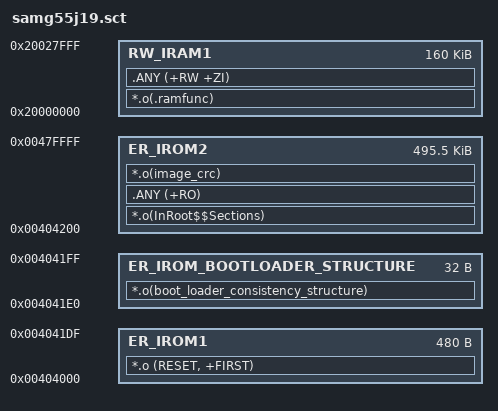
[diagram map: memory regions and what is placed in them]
; *************************************************************
; *** Scatter-Loading Description File generated by uVision ***
; *************************************************************

LR_IROM1 0x00404000 0x0007C000  {    ; load region size_region
  ER_IROM1 0x00404000 0x000001E0  {  ; load address = execution address
   *.o (RESET, +FIRST)
  }
  ER_IROM_BOOTLOADER_STRUCTURE 0x004041E0 0x00000020  {  ; load address = execution address
   *.o(boot_loader_consistency_structure)
  } 
  ER_IROM2 0x00404200 0x0007BE00  {  ; load address = execution address
  *.o(InRoot$$Sections)
   .ANY (+RO)
   *.o(image_crc)
  }
  RW_IRAM1 0x20000000 0x00028000  {  ; RW data
   *.o(.ramfunc)
   .ANY (+RW +ZI)
  }
}

